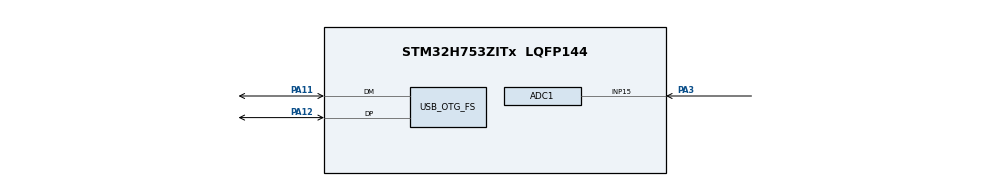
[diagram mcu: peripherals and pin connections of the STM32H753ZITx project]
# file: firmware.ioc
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ADC1.Channel-0\#ChannelRegularConversion=ADC_CHANNEL_15
ADC1.ClockPrescaler=ADC_CLOCK_ASYNC_DIV2
ADC1.ContinuousConvMode=ENABLE
ADC1.ConversionDataManagement=ADC_CONVERSIONDATA_DMA_CIRCULAR
ADC1.NbrOfConversionFlag=1
ADC1.OffsetNumber-0\#ChannelRegularConversion=ADC_OFFSET_NONE
ADC1.OffsetSignedSaturation-0\#ChannelRegularConversion=DISABLE
ADC1.Rank-0\#ChannelRegularConversion=1
ADC1.SamplingTime-0\#ChannelRegularConversion=ADC_SAMPLETIME_8CYCLES_5
ADC1.master=1
CORTEX_M7.CPU_DCache=Disabled
CORTEX_M7.CPU_ICache=Disabled
CORTEX_M7.MPU_Control=__NULL
CORTEX_M7.default_mode_Activation=1
Dma.ADC1.0.Direction=DMA_PERIPH_TO_MEMORY
Dma.ADC1.0.EventEnable=DISABLE
Dma.ADC1.0.FIFOMode=DMA_FIFOMODE_DISABLE
Dma.ADC1.0.Instance=DMA1_Stream0
Dma.ADC1.0.MemDataAlignment=DMA_MDATAALIGN_HALFWORD
Dma.ADC1.0.MemInc=DMA_MINC_ENABLE
Dma.ADC1.0.Mode=DMA_CIRCULAR
Dma.ADC1.0.PeriphDataAlignment=DMA_PDATAALIGN_HALFWORD
Dma.ADC1.0.PeriphInc=DMA_PINC_DISABLE
Dma.ADC1.0.Polarity=HAL_DMAMUX_REQ_GEN_RISING
Dma.ADC1.0.Priority=DMA_PRIORITY_HIGH
Dma.ADC1.0.RequestNumber=1
Dma.ADC1.0.SignalID=NONE
Dma.ADC1.0.SyncEnable=DISABLE
Dma.ADC1.0.SyncPolarity=HAL_DMAMUX_SYNC_NO_EVENT
Dma.ADC1.0.SyncRequestNumber=1
Dma.ADC1.0.SyncSignalID=NONE
Dma.Request0=ADC1
FREERTOS.Tasks01=defaultTask,24,128,StartDefaultTask,Default,NULL,Dynamic,NULL,NULL
FREERTOS.configTOTAL_HEAP_SIZE=32768
FREERTOS.configUSE_NEWLIB_REENTRANT=1
Mcu.Family=STM32H7
Mcu.Name=STM32H753ZITx
Mcu.Package=LQFP144
NUCLEO-H753ZI.BUTTON=1
NUCLEO-H753ZI.LD1=true
NUCLEO-H753ZI.LD2=true
NUCLEO-H753ZI.LD3=true
NUCLEO-H753ZI.VCP=true
NVIC.ADC_IRQn=true\:5\:0\:false\:false\:true\:true\:true\:true\:true
NVIC.DMA1_Stream0_IRQn=true\:5\:0\:false\:false\:true\:true\:false\:true\:true
NVIC.EXTI15_10_IRQn=true\:5\:0\:false\:false\:true\:true\:false\:true\:true
NVIC.OTG_FS_IRQn=true\:5\:0\:false\:false\:true\:true\:true\:true\:true
NVIC.PriorityGroup=NVIC_PRIORITYGROUP_4
NVIC.TIM6_DAC_IRQn=true\:15\:0\:false\:false\:true\:false\:false\:true\:true
NVIC.TimeBase=TIM6_DAC_IRQn
NVIC.TimeBaseIP=TIM6
PA11.Mode=Device_Only
PA11.Signal=USB_OTG_FS_DM
PA12.Mode=Device_Only
PA12.Signal=USB_OTG_FS_DP
PA3.Signal=ADCx_INP15
PC14-OSC32_IN\ (OSC32_IN).Signal=RCC_OSC32_IN
PC15-OSC32_OUT\ (OSC32_OUT).Signal=RCC_OSC32_OUT
PD8.Signal=USART3_TX
PD9.Signal=USART3_RX
PH0-OSC_IN\ (PH0).Signal=RCC_OSC_IN
PH1-OSC_OUT\ (PH1).Signal=RCC_OSC_OUT
ProjectManager.HeapSize=0x200
ProjectManager.StackSize=0x400
ProjectManager.TargetToolchain=STM32CubeIDE
RCC.ADCFreq_Value=80000000
RCC.APB1Freq_Value=120000000
RCC.APB2Freq_Value=120000000
RCC.APB3Freq_Value=120000000
RCC.APB4Freq_Value=120000000
RCC.CortexFreq_Value=480000000
RCC.D1PPRE=RCC_APB3_DIV2
RCC.D2PPRE1=RCC_APB1_DIV2
RCC.D2PPRE2=RCC_APB2_DIV2
RCC.D3PPRE=RCC_APB4_DIV2
RCC.DIVM1=4
RCC.DIVM2=4
RCC.DIVN1=60
RCC.DIVN2=10
RCC.DIVQ1=4
RCC.HCLKFreq_Value=240000000
RCC.HPRE=RCC_HCLK_DIV2
RCC.HSE_VALUE=8000000
RCC.PLL2FRACN=0
RCC.PLL3FRACN=0
RCC.PLLFRACN=0
RCC.PWR_Regulator_Voltage_Scale=PWR_REGULATOR_VOLTAGE_SCALE0
RCC.SYSCLKFreq_VALUE=480000000
RCC.SYSCLKSource=RCC_SYSCLKSOURCE_PLLCLK
RCC.USBCLockSelection=RCC_USBCLKSOURCE_HSI48
RCC.USBFreq_Value=48000000
SH.ADCx_INP15.0=ADC1_INP15,IN15-Single-Ended
USB_DEVICE.CLASS_NAME_FS=CDC
USB_DEVICE.VirtualMode-CDC_FS=Cdc
USB_DEVICE.VirtualModeFS=Cdc_FS
USB_OTG_FS.VirtualMode=Device_Only
VP_FREERTOS_VS_CMSIS_V2.Mode=CMSIS_V2
VP_MEMORYMAP_VS_MEMORYMAP.Mode=CurAppReg
VP_NUCLEO-H753ZI_VS_BSP_COMMON.Mode=COMMON
VP_SYS_VS_tim6.Mode=TIM6
VP_USB_DEVICE_VS_USB_DEVICE_CDC_FS.Mode=CDC_FS
board=NUCLEO-H753ZI

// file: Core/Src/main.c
/* USER CODE BEGIN Header */
/**
  ******************************************************************************
  * @file           : main.c
  * @brief          : Main program body
  ******************************************************************************
  * @attention
  *
  * Copyright (c) 2026 STMicroelectronics.
  * All rights reserved.
  *
  * This software is licensed under terms that can be found in the LICENSE file
  * in the root directory of this software component.
  * If no LICENSE file comes with this software, it is provided AS-IS.
  *
  ******************************************************************************
  */
/* USER CODE END Header */
#include "main.h"
#include "FreeRTOS.h"
#include "cmsis_os2.h"
#include "usb_device.h"

/* USER CODE BEGIN Includes */
#include "arm_math.h"
#include "usbd_cdc_if.h"
#include <string.h>
#include <stdbool.h>
/* USER CODE END Includes */

/* USER CODE BEGIN PD */
#define FRAME_SYNC_0 0xAA
#define FRAME_SYNC_1 0x55
#define FRAME_TYPE_WAVEFORM 0x01

#define WAVEFORM_SAMPLES 2048 // half of DMA buffer
#define MAG_BINS (FFT_SIZE / 2) // 512

// payload = 16 byte header + samples + magnitudes
#define PAYLOAD_HDR_BYTES 16
#define PAYLOAD_BYTES (PAYLOAD_HDR_BYTES + WAVEFORM_SAMPLES * 2 + MAG_BINS * 4)

// full frame is 2 sync + 1 type + 2 length + payload + crc = 7
#define FRAME_OVERHEAD 7
#define FRAME_TOTAL_BYTES (FRAME_OVERHEAD + PAYLOAD_BYTES)

/* USER CODE END PD */

COM_InitTypeDef BspCOMInit;
ADC_HandleTypeDef hadc1;
DMA_HandleTypeDef hdma_adc1;

/* Definitions for defaultTask */
osThreadId_t defaultTaskHandle;
const osThreadAttr_t defaultTask_attributes = {
  .name = "defaultTask",
  .stack_size = 256 * 4,
  .priority = (osPriority_t) osPriorityNormal,
};
/* USER CODE BEGIN PV */
#define ADC_BUFFER_SIZE 4096
#define FFT_SIZE 1024

#define HANN_SIZE FFT_SIZE
static float32_t hann_window[HANN_SIZE];

__attribute__((section(".adc_buffer"), aligned(32)))
uint16_t adc_buffer[ADC_BUFFER_SIZE];

volatile uint32_t dma_half_count = 0;
volatile uint32_t dma_full_count = 0;

// FFT buffers (can stay in cacheable memory as only DMA buffer needs MPU)
static float32_t fft_input[FFT_SIZE];
static float32_t fft_output[FFT_SIZE]; // [r0, i0, r1, i1 ...]
static float32_t fft_magnitudes[FFT_SIZE / 2]; // half-spectrum, real to conjugate symmetric
static arm_rfft_fast_instance_f32 fft_inst;

volatile uint32_t measured_sample_rate = 0;

// Primitives for FreeRTOS
osSemaphoreId_t adcDataSemaphore;
osMessageQueueId_t adcQueue;

// Task handles
osThreadId_t acquisitionTaskHandle;
osThreadId_t processingTaskHandle;

// Shared state (processing to comms), raw peak bin/mag, protect later with mutex
typedef struct {
    uint32_t peak_bin;
    float32_t peak_magnitude;
    uint32_t timestamp_tick;
} ProcessingResults_t;

volatile ProcessingResults_t latest_results;

// message for queue, tell which half of buffer is ready
typedef enum {
	BUFFER_HALF_FIRST = 0,
	BUFFER_HALF_SECOND = 1,
} BufferHalf_t;

// binary frame buffer 6167 bytes - too big for task stack so we make it static global
static uint8_t frame_buffer[FRAME_TOTAL_BYTES];

// usb transmit stats for debugging
volatile uint32_t usb_tx_ok = 0;
volatile uint32_t usb_tx_busy_drops = 0;

static uint16_t latest_samples[WAVEFORM_SAMPLES];
static float32_t latest_magnitudes[MAG_BINS];
/* USER CODE END PV */

void SystemClock_Config(void);
static void MX_GPIO_Init(void);
static void MX_DMA_Init(void);
static void MX_ADC1_Init(void);
void StartDefaultTask(void *argument);

/* USER CODE BEGIN PFP */
static void MPU_Config(void);
static void AcquisitionTask(void *argument);
static void ProcessingTask(void *argument);
static bool build_and_send_frame(void);
/* USER CODE END PFP */

int main(void)
{

  /* USER CODE BEGIN 1 */
	MPU_Config();
	SCB_EnableICache();
	SCB_EnableDCache();
  /* USER CODE END 1 */

  /* MCU Configuration--------------------------------------------------------*/

  /* Reset of all peripherals, Initializes the Flash interface and the Systick. */
  HAL_Init();

  /* Configure the system clock */
  SystemClock_Config();

  /* Initialize all configured peripherals */
  MX_GPIO_Init();
  MX_DMA_Init();
  MX_ADC1_Init();
  /* USER CODE BEGIN 2 */
  HAL_ADC_Start_DMA(&hadc1, (uint32_t*)adc_buffer, ADC_BUFFER_SIZE);
  if (arm_rfft_fast_init_f32(&fft_inst, FFT_SIZE) != ARM_MATH_SUCCESS) {
	  Error_Handler();
  }
  for (int n = 0; n < HANN_SIZE; n++) {
      hann_window[n] = 0.5f * (1.0f - cosf(2.0f * 3.14159265358979f * (float)n / (float)(HANN_SIZE - 1)));
  }
  /* USER CODE END 2 */

  /* Init scheduler */
  osKernelInitialize();

  /* USER CODE BEGIN RTOS_SEMAPHORES */
  /* add semaphores, ... */
  adcDataSemaphore = osSemaphoreNew(4, 0, NULL);
  /* USER CODE END RTOS_SEMAPHORES */

  /* USER CODE BEGIN RTOS_QUEUES */
  /* add queues, ... */
  adcQueue = osMessageQueueNew(8, sizeof(BufferHalf_t), NULL);
  /* USER CODE END RTOS_QUEUES */

  /* Create the thread(s) */
  /* creation of defaultTask */
  defaultTaskHandle = osThreadNew(StartDefaultTask, NULL, &defaultTask_attributes);

  /* USER CODE BEGIN RTOS_THREADS */
  /* add threads, ... */
  const osThreadAttr_t acq_attr = {
		  .name = "AcqTask",
		  .stack_size = 1024,
		  .priority = (osPriority_t)osPriorityHigh,
  };
  acquisitionTaskHandle = osThreadNew(AcquisitionTask, NULL, &acq_attr);

  const osThreadAttr_t proc_attr = {
		  .name = "ProcTask",
		  .stack_size = 4096, // fft needs some stack
		  .priority = (osPriority_t)osPriorityNormal,
  };
  processingTaskHandle = osThreadNew(ProcessingTask, NULL, &proc_attr);
  /* USER CODE END RTOS_THREADS */

  /* Initialize leds */
  BSP_LED_Init(LED_GREEN);
  BSP_LED_Init(LED_YELLOW);
  BSP_LED_Init(LED_RED);

  /* Initialize USER push-button, will be used to trigger an interrupt each time it's pressed.*/
  BSP_PB_Init(BUTTON_USER, BUTTON_MODE_EXTI);

  /* Initialize COM1 port (115200, 8 bits (7-bit data + 1 stop bit), no parity */
  BspCOMInit.BaudRate   = 115200;
  BspCOMInit.WordLength = COM_WORDLENGTH_8B;
  BspCOMInit.StopBits   = COM_STOPBITS_1;
  BspCOMInit.Parity     = COM_PARITY_NONE;
  BspCOMInit.HwFlowCtl  = COM_HWCONTROL_NONE;
  if (BSP_COM_Init(COM1, &BspCOMInit) != BSP_ERROR_NONE)
  {
    Error_Handler();
  }

  /* Start scheduler */
  osKernelStart();

  /* We should never get here as control is now taken by the scheduler */

  /* Infinite loop */
  while (1)
  {

  }
}

void SystemClock_Config(void)
{
  RCC_OscInitTypeDef RCC_OscInitStruct = {0};
  RCC_ClkInitTypeDef RCC_ClkInitStruct = {0};

  /** Supply configuration update enable
  */
  HAL_PWREx_ConfigSupply(PWR_LDO_SUPPLY);

  /** Configure the main internal regulator output voltage
  */
  __HAL_PWR_VOLTAGESCALING_CONFIG(PWR_REGULATOR_VOLTAGE_SCALE0);

  while(!__HAL_PWR_GET_FLAG(PWR_FLAG_VOSRDY)) {}

  /** Initializes the RCC Oscillators according to the specified parameters
  * in the RCC_OscInitTypeDef structure.
  */
  RCC_OscInitStruct.OscillatorType = RCC_OSCILLATORTYPE_HSI48|RCC_OSCILLATORTYPE_HSI;
  RCC_OscInitStruct.HSIState = RCC_HSI_DIV1;
  RCC_OscInitStruct.HSICalibrationValue = RCC_HSICALIBRATION_DEFAULT;
  RCC_OscInitStruct.HSI48State = RCC_HSI48_ON;
  RCC_OscInitStruct.PLL.PLLState = RCC_PLL_ON;
  RCC_OscInitStruct.PLL.PLLSource = RCC_PLLSOURCE_HSI;
  RCC_OscInitStruct.PLL.PLLM = 4;
  RCC_OscInitStruct.PLL.PLLN = 60;
  RCC_OscInitStruct.PLL.PLLP = 2;
  RCC_OscInitStruct.PLL.PLLQ = 4;
  RCC_OscInitStruct.PLL.PLLR = 2;
  RCC_OscInitStruct.PLL.PLLRGE = RCC_PLL1VCIRANGE_3;
  RCC_OscInitStruct.PLL.PLLVCOSEL = RCC_PLL1VCOWIDE;
  RCC_OscInitStruct.PLL.PLLFRACN = 0;
  if (HAL_RCC_OscConfig(&RCC_OscInitStruct) != HAL_OK)
  {
    Error_Handler();
  }

  /** Initializes the CPU, AHB and APB buses clocks
  */
  RCC_ClkInitStruct.ClockType = RCC_CLOCKTYPE_HCLK|RCC_CLOCKTYPE_SYSCLK
                              |RCC_CLOCKTYPE_PCLK1|RCC_CLOCKTYPE_PCLK2
                              |RCC_CLOCKTYPE_D3PCLK1|RCC_CLOCKTYPE_D1PCLK1;
  RCC_ClkInitStruct.SYSCLKSource = RCC_SYSCLKSOURCE_PLLCLK;
  RCC_ClkInitStruct.SYSCLKDivider = RCC_SYSCLK_DIV1;
  RCC_ClkInitStruct.AHBCLKDivider = RCC_HCLK_DIV2;
  RCC_ClkInitStruct.APB3CLKDivider = RCC_APB3_DIV2;
  RCC_ClkInitStruct.APB1CLKDivider = RCC_APB1_DIV2;
  RCC_ClkInitStruct.APB2CLKDivider = RCC_APB2_DIV2;
  RCC_ClkInitStruct.APB4CLKDivider = RCC_APB4_DIV2;

  if (HAL_RCC_ClockConfig(&RCC_ClkInitStruct, FLASH_LATENCY_4) != HAL_OK)
  {
    Error_Handler();
  }
}

static void MX_ADC1_Init(void)
{

  ADC_MultiModeTypeDef multimode = {0};
  ADC_ChannelConfTypeDef sConfig = {0};

  /** Common config
  */
  hadc1.Instance = ADC1;
  hadc1.Init.ClockPrescaler = ADC_CLOCK_ASYNC_DIV2;
  hadc1.Init.Resolution = ADC_RESOLUTION_16B;
  hadc1.Init.ScanConvMode = ADC_SCAN_DISABLE;
  hadc1.Init.EOCSelection = ADC_EOC_SINGLE_CONV;
  hadc1.Init.LowPowerAutoWait = DISABLE;
  hadc1.Init.ContinuousConvMode = ENABLE;
  hadc1.Init.NbrOfConversion = 1;
  hadc1.Init.DiscontinuousConvMode = DISABLE;
  hadc1.Init.ExternalTrigConv = ADC_SOFTWARE_START;
  hadc1.Init.ExternalTrigConvEdge = ADC_EXTERNALTRIGCONVEDGE_NONE;
  hadc1.Init.ConversionDataManagement = ADC_CONVERSIONDATA_DMA_CIRCULAR;
  hadc1.Init.Overrun = ADC_OVR_DATA_PRESERVED;
  hadc1.Init.LeftBitShift = ADC_LEFTBITSHIFT_NONE;
  hadc1.Init.OversamplingMode = DISABLE;
  hadc1.Init.Oversampling.Ratio = 1;
  if (HAL_ADC_Init(&hadc1) != HAL_OK)
  {
    Error_Handler();
  }

  /** Configure the ADC multi-mode
  */
  multimode.Mode = ADC_MODE_INDEPENDENT;
  if (HAL_ADCEx_MultiModeConfigChannel(&hadc1, &multimode) != HAL_OK)
  {
    Error_Handler();
  }

  /** Configure Regular Channel
  */
  sConfig.Channel = ADC_CHANNEL_15;
  sConfig.Rank = ADC_REGULAR_RANK_1;
  sConfig.SamplingTime = ADC_SAMPLETIME_8CYCLES_5;
  sConfig.SingleDiff = ADC_SINGLE_ENDED;
  sConfig.OffsetNumber = ADC_OFFSET_NONE;
  sConfig.Offset = 0;
  sConfig.OffsetSignedSaturation = DISABLE;
  if (HAL_ADC_ConfigChannel(&hadc1, &sConfig) != HAL_OK)
  {
    Error_Handler();
  }

}

static void MX_DMA_Init(void)
{

  /* DMA controller clock enable */
  __HAL_RCC_DMA1_CLK_ENABLE();

  /* DMA interrupt init */
  /* DMA1_Stream0_IRQn interrupt configuration */
  HAL_NVIC_SetPriority(DMA1_Stream0_IRQn, 5, 0);
  HAL_NVIC_EnableIRQ(DMA1_Stream0_IRQn);

}

static void MX_GPIO_Init(void)
{

  /* GPIO Ports Clock Enable */
  __HAL_RCC_GPIOC_CLK_ENABLE();
  __HAL_RCC_GPIOH_CLK_ENABLE();
  __HAL_RCC_GPIOA_CLK_ENABLE();

}

/* USER CODE BEGIN 4 */
void HAL_ADC_ConvHalfCpltCallback(ADC_HandleTypeDef *hadc) {
    dma_half_count++;
    /* First half of buffer is fresh. Give semaphore to wake acquisition task. */
    if (adcDataSemaphore != NULL) {
        osSemaphoreRelease(adcDataSemaphore);
    }
}

void HAL_ADC_ConvCpltCallback(ADC_HandleTypeDef *hadc) {
    dma_full_count++;
    /* Second half of buffer is fresh. */
    if (adcDataSemaphore != NULL) {
        osSemaphoreRelease(adcDataSemaphore);
    }
}

static void AcquisitionTask(void *argument) {
    BufferHalf_t next_half = BUFFER_HALF_FIRST;

    for (;;) {
        // Block until DMA callback gives semaphore
        osSemaphoreAcquire(adcDataSemaphore, osWaitForever);

        // Post which half is now fresh to the processing queue
        osMessageQueuePut(adcQueue, &next_half, 0U, 0U);

        // Alternate for next iteration
        next_half = (next_half == BUFFER_HALF_FIRST) ? BUFFER_HALF_SECOND : BUFFER_HALF_FIRST;
    }
}

static void ProcessingTask(void *argument) {
    BufferHalf_t half;

    for (;;) {
        // Block until acquisition task posts
        if (osMessageQueueGet(adcQueue, &half, NULL, osWaitForever) != osOK) {
            continue;
        }

        // Determine which 2048-sample slice to run FFT over. We still FFT only FFT_SIZE (1024)
        // samples from the start of that half for consistency with earlier behavior.
        uint16_t *src = (half == BUFFER_HALF_FIRST) ? &adc_buffer[0] : &adc_buffer[ADC_BUFFER_SIZE / 2];

        for (int i = 0; i < FFT_SIZE; i++) {
        	fft_input[i] = ((float32_t)src[i] - 32768.0f) * hann_window[i];;
        }
        arm_rfft_fast_f32(&fft_inst, fft_input, fft_output, 0);
        arm_cmplx_mag_f32(fft_output, fft_magnitudes, FFT_SIZE / 2);

        uint32_t best_bin = 1;
        float32_t best_mag = 0.0f;
        for (uint32_t i = 2; i < FFT_SIZE / 2; i++) {
            if (fft_magnitudes[i] > best_mag) {
                best_mag = fft_magnitudes[i];
                best_bin = i;
            }
        }

        memcpy(latest_samples, src, WAVEFORM_SAMPLES * sizeof(uint16_t));
        memcpy(latest_magnitudes, fft_magnitudes, MAG_BINS * sizeof(float32_t));

        // Publish to shared struct (will be mutex-protected later)
        latest_results.peak_bin = best_bin;
        latest_results.peak_magnitude = best_mag;
        latest_results.timestamp_tick = osKernelGetTickCount();
    }
}

extern uint32_t _sadc_buffer;
static void MPU_Config(void) {
	MPU_Region_InitTypeDef mpu = {0};
	HAL_MPU_Disable();

	mpu.Enable           = MPU_REGION_ENABLE;
	mpu.Number           = MPU_REGION_NUMBER0;
	mpu.BaseAddress      = (uint32_t)&_sadc_buffer;
	mpu.Size             = MPU_REGION_SIZE_8KB;
	mpu.AccessPermission = MPU_REGION_FULL_ACCESS;
	mpu.IsBufferable     = MPU_ACCESS_BUFFERABLE;
	mpu.IsCacheable      = MPU_ACCESS_NOT_CACHEABLE;
	mpu.IsShareable      = MPU_ACCESS_SHAREABLE;
	mpu.TypeExtField     = MPU_TEX_LEVEL0;
	mpu.SubRegionDisable = 0x00;
	mpu.DisableExec      = MPU_INSTRUCTION_ACCESS_DISABLE;

	HAL_MPU_ConfigRegion(&mpu);
	HAL_MPU_Enable(MPU_PRIVILEGED_DEFAULT);

}

// CRC16-CCITT, use crcmod library in Python
static uint16_t crc16_ccitt(const uint8_t *data, size_t len) {
    uint16_t crc = 0xFFFF;
    for (size_t i = 0; i < len; i++) {
        crc ^= ((uint16_t)data[i]) << 8;
        for (int b = 0; b < 8; b++) {
            if (crc & 0x8000) {
                crc = (crc << 1) ^ 0x1021;
            } else {
                crc <<= 1;
            }
        }
    }
    return crc;
}

static bool build_and_send_frame(void) {
    uint8_t *p = frame_buffer;

    /* Sync + header */
    *p++ = FRAME_SYNC_0;
    *p++ = FRAME_SYNC_1;
    *p++ = FRAME_TYPE_WAVEFORM;
    *p++ = (uint8_t)(PAYLOAD_BYTES & 0xFF);
    *p++ = (uint8_t)((PAYLOAD_BYTES >> 8) & 0xFF);

    /* Payload: 16-byte header */
    uint8_t *crc_start = p - 3;      /* type + length */
    uint32_t tick = osKernelGetTickCount();
    uint32_t fs = measured_sample_rate;
    uint32_t pbin = latest_results.peak_bin;
    float32_t pmag = latest_results.peak_magnitude;

    memcpy(p, &tick, 4);   p += 4;
    memcpy(p, &fs,   4);   p += 4;
    memcpy(p, &pbin, 4);   p += 4;
    memcpy(p, &pmag, 4);   p += 4;

    /* Payload: waveform samples */
    memcpy(p, latest_samples, WAVEFORM_SAMPLES * sizeof(uint16_t));
    p += WAVEFORM_SAMPLES * sizeof(uint16_t);

    /* Payload: magnitudes */
    memcpy(p, latest_magnitudes, MAG_BINS * sizeof(float32_t));
    p += MAG_BINS * sizeof(float32_t);

    /* CRC over [type + length + payload] */
    size_t crc_len = (size_t)(p - crc_start);
    uint16_t crc = crc16_ccitt(crc_start, crc_len);
    *p++ = (uint8_t)(crc & 0xFF);
    *p++ = (uint8_t)((crc >> 8) & 0xFF);

    /* Attempt transmit — CDC is non-blocking, may return USBD_BUSY */
    uint8_t result = CDC_Transmit_FS(frame_buffer, FRAME_TOTAL_BYTES);
    if (result == USBD_OK) {
        usb_tx_ok++;
        return true;
    } else {
        usb_tx_busy_drops++;
        return false;
    }
}
/* USER CODE END 4 */

void StartDefaultTask(void *argument)
{
  /* init code for USB_DEVICE */
  MX_USB_DEVICE_Init();
  /* USER CODE BEGIN 5 */
  static uint32_t last_full_count = 0;
  static uint32_t last_tick = 0;

  osDelay(2000); // ~2seconds wait
  /* Infinite loop */
  for(;;)
  {
	  uint32_t now = osKernelGetTickCount();
	  if (now - last_tick >= 1000) {
		  uint32_t delta = dma_full_count - last_full_count;
		  measured_sample_rate = delta * ADC_BUFFER_SIZE;
		  last_full_count = dma_full_count;
		  last_tick = now;
	  }

	  build_and_send_frame();

	  HAL_GPIO_TogglePin(LED1_GPIO_PORT, LED1_PIN);

	  osDelay(33);
  }
  /* USER CODE END 5 */
}

void HAL_TIM_PeriodElapsedCallback(TIM_HandleTypeDef *htim)
{
  if (htim->Instance == TIM6)
  {
    HAL_IncTick();
  }
}

void Error_Handler(void)
{
  __disable_irq();
  while (1)
  {
  }
}
